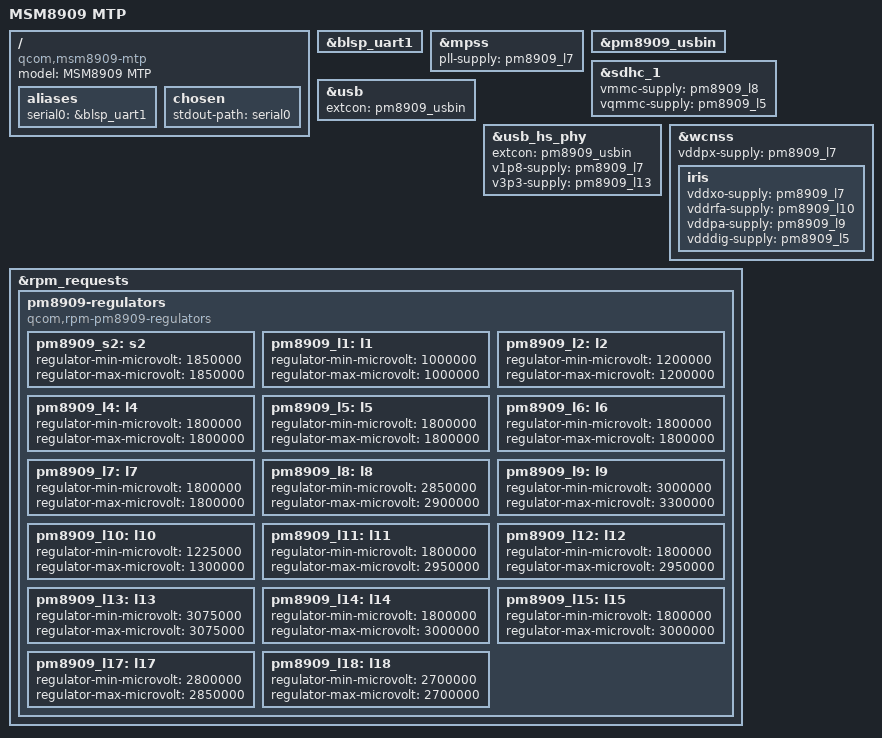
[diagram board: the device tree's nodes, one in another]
// SPDX-License-Identifier: GPL-2.0-only
#include "qcom-msm8909.dtsi"
#include "qcom-pm8909.dtsi"

/ {
	model = "MSM8909 MTP";
	compatible = "qcom,msm8909-mtp", "qcom,msm8909";

	aliases {
		serial0 = &blsp_uart1;
	};

	chosen {
		stdout-path = "serial0";
	};
};

&blsp_uart1 {
	status = "okay";
};

&mpss {
	status = "okay";
	pll-supply = <&pm8909_l7>;
};

&pm8909_usbin {
	status = "okay";
};

&sdhc_1 {
	status = "okay";
	vmmc-supply = <&pm8909_l8>;
	vqmmc-supply = <&pm8909_l5>;
};

&usb {
	status = "okay";
	extcon = <&pm8909_usbin>;
};

&usb_hs_phy {
	extcon = <&pm8909_usbin>;
	v1p8-supply = <&pm8909_l7>;
	v3p3-supply = <&pm8909_l13>;
};

&wcnss {
	status = "okay";
	vddpx-supply = <&pm8909_l7>;

	iris {
		vddxo-supply = <&pm8909_l7>;
		vddrfa-supply = <&pm8909_l10>;
		vddpa-supply = <&pm8909_l9>;
		vdddig-supply = <&pm8909_l5>;
	};
};

&rpm_requests {
	pm8909-regulators {
		compatible = "qcom,rpm-pm8909-regulators";

		/* pm8909_s1 is managed by rpmpd (MSM8909_VDDCX) */
		pm8909_s2: s2 {
			regulator-min-microvolt = <1850000>;
			regulator-max-microvolt = <1850000>;
		};

		pm8909_l1: l1 {
			regulator-min-microvolt = <1000000>;
			regulator-max-microvolt = <1000000>;
		};
		pm8909_l2: l2 {
			regulator-min-microvolt = <1200000>;
			regulator-max-microvolt = <1200000>;
		};
		/* pm8909_l3 is managed by rpmpd (MSM8909_VDDMX) */
		pm8909_l4: l4 {
			regulator-min-microvolt = <1800000>;
			regulator-max-microvolt = <1800000>;
		};
		pm8909_l5: l5 {
			regulator-min-microvolt = <1800000>;
			regulator-max-microvolt = <1800000>;
		};
		pm8909_l6: l6 {
			regulator-min-microvolt = <1800000>;
			regulator-max-microvolt = <1800000>;
		};
		pm8909_l7: l7 {
			regulator-min-microvolt = <1800000>;
			regulator-max-microvolt = <1800000>;
		};
		pm8909_l8: l8 {
			regulator-min-microvolt = <2850000>;
			regulator-max-microvolt = <2900000>;
		};
		pm8909_l9: l9 {
			regulator-min-microvolt = <3000000>;
			regulator-max-microvolt = <3300000>;
		};
		pm8909_l10: l10 {
			regulator-min-microvolt = <1225000>;
			regulator-max-microvolt = <1300000>;
		};
		pm8909_l11: l11 {
			regulator-min-microvolt = <1800000>;
			regulator-max-microvolt = <2950000>;
		};
		pm8909_l12: l12 {
			regulator-min-microvolt = <1800000>;
			regulator-max-microvolt = <2950000>;
		};
		pm8909_l13: l13 {
			regulator-min-microvolt = <3075000>;
			regulator-max-microvolt = <3075000>;
		};
		pm8909_l14: l14 {
			regulator-min-microvolt = <1800000>;
			regulator-max-microvolt = <3000000>;
		};
		pm8909_l15: l15 {
			regulator-min-microvolt = <1800000>;
			regulator-max-microvolt = <3000000>;
		};
		pm8909_l17: l17 {
			regulator-min-microvolt = <2800000>;
			regulator-max-microvolt = <2850000>;
		};
		pm8909_l18: l18 {
			regulator-min-microvolt = <2700000>;
			regulator-max-microvolt = <2700000>;
		};
	};
};
